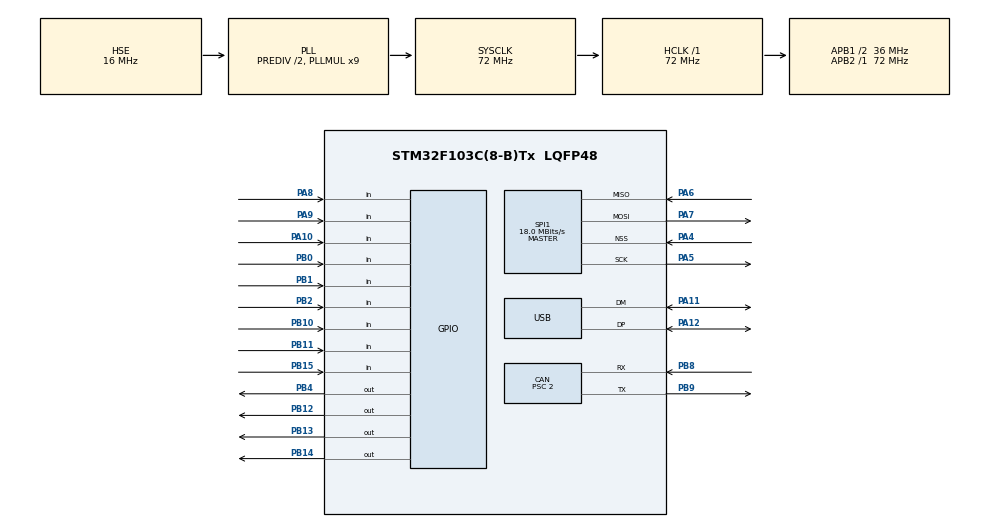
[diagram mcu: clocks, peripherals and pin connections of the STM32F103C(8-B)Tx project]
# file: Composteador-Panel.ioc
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Mcu.Family=STM32F1
PA6.Mode=Full_Duplex_Master
USB_DEVICE.CLASS_NAME_FS=CDC
SPI1.VirtualType=VM_MASTER
PA11.Mode=Device
NVIC.TIM1_UP_IRQn=true\:0\:0\:false\:false\:true\:false\:false\:true
PB11.Signal=GPIO_Input
PB13.Signal=GPIO_Output
PB15.Signal=GPIO_Input
RCC.SYSCLKSource=RCC_SYSCLKSOURCE_PLLCLK
ProjectManager.StackSize=0x400
VP_FREERTOS_VS_CMSIS_V2.Mode=CMSIS_V2
PD1-OSC_OUT.Signal=RCC_OSC_OUT
PA12.Signal=USB_DP
CAN.Prescaler=2
PA4.Mode=NSS_Signal_Hard_Input
SPI1.Direction=SPI_DIRECTION_2LINES
RCC.HCLKFreq_Value=72000000
RCC.APB2TimFreq_Value=72000000
SPI1.CalculateBaudRate=18.0 MBits/s
RCC.AHBFreq_Value=72000000
RCC.HSE_VALUE=16000000
PB2.Signal=GPIO_Input
RCC.PLLMUL=RCC_PLL_MUL9
USB_DEVICE.USBD_SELF_POWERED=1
PA14.Mode=Serial_Wire
VP_SYS_VS_tim1.Mode=TIM1
PA8.Signal=GPIO_Input
SPI1.VirtualNSS=VM_NSSHARD
CAN.CalculateTimeQuantum=55.55555555555556
Mcu.Package=LQFP48
PB9.Signal=CAN_TX
PA6.Signal=SPI1_MISO
PB1.Signal=GPIO_Input
NVIC.TimeBase=TIM1_UP_IRQn
NVIC.TimeBaseIP=TIM1
PA10.Signal=GPIO_Input
RCC.APB1TimFreq_Value=72000000
SPI1.BaudRatePrescaler=SPI_BAUDRATEPRESCALER_4
PB4.Signal=GPIO_Output
PA5.Mode=Full_Duplex_Master
FREERTOS.Tasks01=defaultTask,24,128,StartDefaultTask,Default,NULL,Dynamic,NULL,NULL
PA7.Mode=Full_Duplex_Master
PD1-OSC_OUT.Mode=HSE-External-Clock-Source
USB_DEVICE.VirtualModeFS=Cdc_FS
CAN.CalculateBaudRate=1000000
RCC.USBPrescaler=RCC_USBCLKSOURCE_PLL_DIV1_5
PD0-OSC_IN.Signal=RCC_OSC_IN
RCC.APB1CLKDivider=RCC_HCLK_DIV2
CAN.CalculateTimeBit=999.99
PA13.Signal=SYS_JTMS-SWDIO
CAN.BS2=CAN_BS2_2TQ
CAN.BS1=CAN_BS1_15TQ
ProjectManager.TargetToolchain=STM32CubeIDE
VP_USB_DEVICE_VS_USB_DEVICE_CDC_FS.Mode=CDC_FS
PB9.Mode=CAN_Activate
PA9.Signal=GPIO_Input
RCC.USBFreq_Value=48000000
PB10.Signal=GPIO_Input
PD0-OSC_IN.Mode=HSE-External-Clock-Source
PB14.Signal=GPIO_Output
PA5.Signal=SPI1_SCK
board=custom
RCC.APB2Freq_Value=72000000
SPI1.Mode=SPI_MODE_MASTER
NVIC.USB_LP_CAN1_RX0_IRQn=true\:5\:0\:false\:false\:true\:true\:false\:true
PA13.Mode=Serial_Wire
Mcu.Name=STM32F103C(8-B)Tx
PA4.Signal=SPI1_NSS
RCC.SYSCLKFreq_VALUE=72000000
PA12.Mode=Device
RCC.HSEDivPLL=RCC_HSE_PREDIV_DIV2
PA11.Signal=USB_DM
PA14.Signal=SYS_JTCK-SWCLK
ProjectManager.HeapSize=0x200
NVIC.PriorityGroup=NVIC_PRIORITYGROUP_4
PB8.Mode=CAN_Activate
PB8.Signal=CAN_RX
RCC.APB1Freq_Value=36000000
VP_CRC_VS_CRC.Mode=CRC_Activate
PB0.Signal=GPIO_Input
USB_DEVICE.VirtualMode=Cdc
PB12.Signal=GPIO_Output
PA7.Signal=SPI1_MOSI

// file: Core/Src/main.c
/* USER CODE BEGIN Header */
/**
  ******************************************************************************
  * @file           : main.c
  * @brief          : Main program body
  ******************************************************************************
  * @attention
  *
  * <h2><center>&copy; Copyright (c) 2021 STMicroelectronics.
  * All rights reserved.</center></h2>
  *
  * This software component is licensed by ST under BSD 3-Clause license,
  * the "License"; You may not use this file except in compliance with the
  * License. You may obtain a copy of the License at:
  *                        opensource.org/licenses/BSD-3-Clause
  *
  ******************************************************************************
  */
/* USER CODE END Header */
#include "main.h"
#include "cmsis_os.h"
#include "usb_device.h"

/* USER CODE BEGIN Includes */
#include "flash.h"
#include "usb.h"
#include "control.h"
#include "can.h"
#include "interface.h"
/* USER CODE END Includes */

CAN_HandleTypeDef hcan;

CRC_HandleTypeDef hcrc;

SPI_HandleTypeDef hspi1;

/* Definitions for defaultTask */
osThreadId_t defaultTaskHandle;
const osThreadAttr_t defaultTask_attributes = {
  .name = "defaultTask",
  .stack_size = 128 * 4,
  .priority = (osPriority_t) osPriorityNormal,
};

void SystemClock_Config(void);
static void MX_GPIO_Init(void);
static void MX_CAN_Init(void);
static void MX_SPI1_Init(void);
static void MX_CRC_Init(void);
void StartDefaultTask(void *argument);

int main(void)
{

  /* MCU Configuration--------------------------------------------------------*/

  /* Reset of all peripherals, Initializes the Flash interface and the Systick. */
  HAL_Init();

  /* Configure the system clock */
  SystemClock_Config();

  /* Initialize all configured peripherals */
  MX_GPIO_Init();
  MX_CAN_Init();
  MX_SPI1_Init();
  MX_CRC_Init();
  /* USER CODE BEGIN 2 */

  init_flash();
  control_init();
  usb_set_high_impedance_dp();

  /* USER CODE END 2 */

  /* Init scheduler */
  osKernelInitialize();

  /* Create the thread(s) */
  /* creation of defaultTask */
  defaultTaskHandle = osThreadNew(StartDefaultTask, NULL, &defaultTask_attributes);

  /* Start scheduler */
  osKernelStart();

  /* We should never get here as control is now taken by the scheduler */
  /* Infinite loop */
  while (1)
  {

  }
}

void SystemClock_Config(void)
{
  RCC_OscInitTypeDef RCC_OscInitStruct = {0};
  RCC_ClkInitTypeDef RCC_ClkInitStruct = {0};
  RCC_PeriphCLKInitTypeDef PeriphClkInit = {0};

  /** Initializes the RCC Oscillators according to the specified parameters
  * in the RCC_OscInitTypeDef structure.
  */
  RCC_OscInitStruct.OscillatorType = RCC_OSCILLATORTYPE_HSE;
  RCC_OscInitStruct.HSEState = RCC_HSE_BYPASS;
  RCC_OscInitStruct.HSEPredivValue = RCC_HSE_PREDIV_DIV2;
  RCC_OscInitStruct.HSIState = RCC_HSI_ON;
  RCC_OscInitStruct.PLL.PLLState = RCC_PLL_ON;
  RCC_OscInitStruct.PLL.PLLSource = RCC_PLLSOURCE_HSE;
  RCC_OscInitStruct.PLL.PLLMUL = RCC_PLL_MUL9;
  if (HAL_RCC_OscConfig(&RCC_OscInitStruct) != HAL_OK)
  {
    Error_Handler();
  }
  /** Initializes the CPU, AHB and APB buses clocks
  */
  RCC_ClkInitStruct.ClockType = RCC_CLOCKTYPE_HCLK|RCC_CLOCKTYPE_SYSCLK
                              |RCC_CLOCKTYPE_PCLK1|RCC_CLOCKTYPE_PCLK2;
  RCC_ClkInitStruct.SYSCLKSource = RCC_SYSCLKSOURCE_PLLCLK;
  RCC_ClkInitStruct.AHBCLKDivider = RCC_SYSCLK_DIV1;
  RCC_ClkInitStruct.APB1CLKDivider = RCC_HCLK_DIV2;
  RCC_ClkInitStruct.APB2CLKDivider = RCC_HCLK_DIV1;

  if (HAL_RCC_ClockConfig(&RCC_ClkInitStruct, FLASH_LATENCY_2) != HAL_OK)
  {
    Error_Handler();
  }
  PeriphClkInit.PeriphClockSelection = RCC_PERIPHCLK_USB;
  PeriphClkInit.UsbClockSelection = RCC_USBCLKSOURCE_PLL_DIV1_5;
  if (HAL_RCCEx_PeriphCLKConfig(&PeriphClkInit) != HAL_OK)
  {
    Error_Handler();
  }
}

static void MX_CAN_Init(void)
{

  hcan.Instance = CAN1;
  hcan.Init.Prescaler = 2;
  hcan.Init.Mode = CAN_MODE_NORMAL;
  hcan.Init.SyncJumpWidth = CAN_SJW_1TQ;
  hcan.Init.TimeSeg1 = CAN_BS1_15TQ;
  hcan.Init.TimeSeg2 = CAN_BS2_2TQ;
  hcan.Init.TimeTriggeredMode = DISABLE;
  hcan.Init.AutoBusOff = DISABLE;
  hcan.Init.AutoWakeUp = DISABLE;
  hcan.Init.AutoRetransmission = DISABLE;
  hcan.Init.ReceiveFifoLocked = DISABLE;
  hcan.Init.TransmitFifoPriority = DISABLE;
  if (HAL_CAN_Init(&hcan) != HAL_OK)
  {
    Error_Handler();
  }

}

static void MX_CRC_Init(void)
{

  /* USER CODE BEGIN CRC_Init 1 */

  /*
  hcrc.Instance = CRC;
  hcrc.Init.DefaultPolynomialUse = DEFAULT_POLYNOMIAL_ENABLE;
  hcrc.Init.DefaultInitValueUse = DEFAULT_INIT_VALUE_ENABLE;
  hcrc.Init.InputDataInversionMode = CRC_INPUTDATA_INVERSION_BYTE;
  hcrc.Init.OutputDataInversionMode = CRC_OUTPUTDATA_INVERSION_ENABLE;
  hcrc.InputDataFormat = CRC_INPUTDATA_FORMAT_BYTES;
  */

  /* USER CODE END CRC_Init 1 */
  hcrc.Instance = CRC;
  if (HAL_CRC_Init(&hcrc) != HAL_OK)
  {
    Error_Handler();
  }

}

static void MX_SPI1_Init(void)
{

  /* SPI1 parameter configuration*/
  hspi1.Instance = SPI1;
  hspi1.Init.Mode = SPI_MODE_MASTER;
  hspi1.Init.Direction = SPI_DIRECTION_2LINES;
  hspi1.Init.DataSize = SPI_DATASIZE_8BIT;
  hspi1.Init.CLKPolarity = SPI_POLARITY_LOW;
  hspi1.Init.CLKPhase = SPI_PHASE_1EDGE;
  hspi1.Init.NSS = SPI_NSS_HARD_INPUT;
  hspi1.Init.BaudRatePrescaler = SPI_BAUDRATEPRESCALER_4;
  hspi1.Init.FirstBit = SPI_FIRSTBIT_MSB;
  hspi1.Init.TIMode = SPI_TIMODE_DISABLE;
  hspi1.Init.CRCCalculation = SPI_CRCCALCULATION_DISABLE;
  hspi1.Init.CRCPolynomial = 10;
  if (HAL_SPI_Init(&hspi1) != HAL_OK)
  {
    Error_Handler();
  }

}

static void MX_GPIO_Init(void)
{
  GPIO_InitTypeDef GPIO_InitStruct = {0};

  /* GPIO Ports Clock Enable */
  __HAL_RCC_GPIOD_CLK_ENABLE();
  __HAL_RCC_GPIOA_CLK_ENABLE();
  __HAL_RCC_GPIOB_CLK_ENABLE();

  /*Configure GPIO pin Output Level */
  HAL_GPIO_WritePin(GPIOB, GPIO_PIN_12|GPIO_PIN_13|GPIO_PIN_14|GPIO_PIN_4, GPIO_PIN_RESET);

  /*Configure GPIO pins : PB0 PB1 PB2 PB10
                           PB11 PB15 */
  GPIO_InitStruct.Pin = GPIO_PIN_0|GPIO_PIN_1|GPIO_PIN_2|GPIO_PIN_10
                          |GPIO_PIN_11|GPIO_PIN_15;
  GPIO_InitStruct.Mode = GPIO_MODE_INPUT;
  GPIO_InitStruct.Pull = GPIO_NOPULL;
  HAL_GPIO_Init(GPIOB, &GPIO_InitStruct);

  /*Configure GPIO pins : PB12 PB13 PB14 PB4 */
  GPIO_InitStruct.Pin = GPIO_PIN_12|GPIO_PIN_13|GPIO_PIN_14|GPIO_PIN_4;
  GPIO_InitStruct.Mode = GPIO_MODE_OUTPUT_PP;
  GPIO_InitStruct.Pull = GPIO_NOPULL;
  GPIO_InitStruct.Speed = GPIO_SPEED_FREQ_LOW;
  HAL_GPIO_Init(GPIOB, &GPIO_InitStruct);

  /*Configure GPIO pins : PA8 PA9 PA10 */
  GPIO_InitStruct.Pin = GPIO_PIN_8|GPIO_PIN_9|GPIO_PIN_10;
  GPIO_InitStruct.Mode = GPIO_MODE_INPUT;
  GPIO_InitStruct.Pull = GPIO_NOPULL;
  HAL_GPIO_Init(GPIOA, &GPIO_InitStruct);

}

void StartDefaultTask(void *argument)
{
  /* init code for USB_DEVICE */
  MX_USB_DEVICE_Init();
  for(;;)
  {
    osDelay(1);
  }
}

 /**
  * @brief  Period elapsed callback in non blocking mode
  * @note   This function is called  when TIM1 interrupt took place, inside
  * HAL_TIM_IRQHandler(). It makes a direct call to HAL_IncTick() to increment
  * a global variable "uwTick" used as application time base.
  * @param  htim : TIM handle
  * @retval None
  */
void HAL_TIM_PeriodElapsedCallback(TIM_HandleTypeDef *htim)
{
  if (htim->Instance == TIM1) {
    HAL_IncTick();
  }
}

void Error_Handler(void)
{
  __disable_irq();
  while (1)
  {
  }
}

/************************ (C) COPYRIGHT STMicroelectronics *****END OF FILE****/
